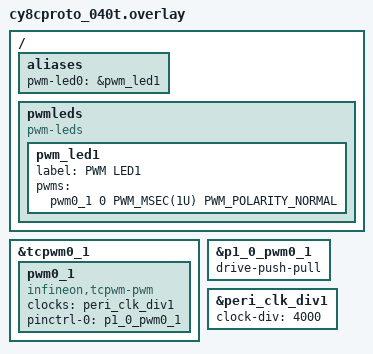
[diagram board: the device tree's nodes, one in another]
/*
 * SPDX-FileCopyrightText: Copyright (c) 2026 Infineon Technologies AG,
 * SPDX-FileCopyrightText: or an affiliate of Infineon Technologies AG. All rights reserved.
 *
 * SPDX-License-Identifier: Apache-2.0
 */

#include <zephyr/dt-bindings/pwm/pwm.h>

/ {
	aliases {
		pwm-led0 = &pwm_led1;
	};

	pwmleds {
		compatible = "pwm-leds";

		pwm_led1: pwm_led1 {
			label = "PWM LED1";
			pwms = <&pwm0_1 0 PWM_MSEC(1U) PWM_POLARITY_NORMAL>;
		};
	};
};

&tcpwm0_1 {
	status = "okay";

	pwm0_1 {
		clocks = <&peri_clk_div1>;
		compatible = "infineon,tcpwm-pwm";
		status = "okay";
		pinctrl-0 = <&p1_0_pwm0_1>;
		pinctrl-names = "default";
	};
};

&p1_0_pwm0_1 {
	drive-push-pull;
};

/* Divide the 48MHz clk_hf down so a 1-second period fits the 16-bit PWM counter */
&peri_clk_div1 {
	status = "okay";
	clock-div = <4000>;
};
